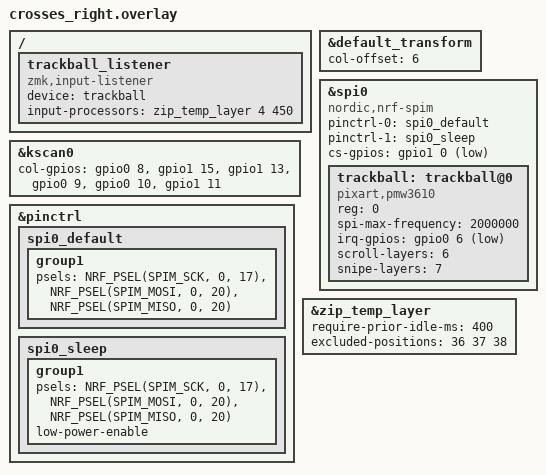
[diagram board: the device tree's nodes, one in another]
/*
 * Copyright (c) 2020 ZMK Contributors
 *
 * SPDX-License-Identifier: MIT
 */
 
#include "crosses.dtsi"
#include <input/processors.dtsi>

&default_transform {
    col-offset = <6>;
}; 

&kscan0 {
	col-gpios
		= <&gpio0 8 (GPIO_ACTIVE_HIGH | GPIO_PULL_DOWN)>
		, <&gpio1 15 (GPIO_ACTIVE_HIGH | GPIO_PULL_DOWN)>
		, <&gpio1 13 (GPIO_ACTIVE_HIGH | GPIO_PULL_DOWN)>
		, <&gpio0 9 (GPIO_ACTIVE_HIGH | GPIO_PULL_DOWN)>
		, <&gpio0 10  (GPIO_ACTIVE_HIGH | GPIO_PULL_DOWN)>
		, <&gpio1 11 (GPIO_ACTIVE_HIGH | GPIO_PULL_DOWN)>
		
		;
};


// trackball bus
&pinctrl {
    spi0_default: spi0_default {
        group1 {
            psels = <NRF_PSEL(SPIM_SCK, 0, 17)>,
                <NRF_PSEL(SPIM_MOSI, 0, 20)>,
                <NRF_PSEL(SPIM_MISO, 0, 20)>;
        };
    };

    spi0_sleep: spi0_sleep {
        group1 {
            psels = <NRF_PSEL(SPIM_SCK, 0, 17)>,
                <NRF_PSEL(SPIM_MOSI, 0, 20)>,
                <NRF_PSEL(SPIM_MISO, 0, 20)>;
            low-power-enable;
        };
    };
};

&spi0 {
    status = "okay";
    compatible = "nordic,nrf-spim";
    pinctrl-0 = <&spi0_default>;
    pinctrl-1 = <&spi0_sleep>;
    pinctrl-names = "default", "sleep";
    cs-gpios = <&gpio1 0 GPIO_ACTIVE_LOW>;

    trackball: trackball@0 {
        status = "okay";
        compatible = "pixart,pmw3610";
        reg = <0>;
        spi-max-frequency = <2000000>;
        irq-gpios = <&gpio0 6 (GPIO_ACTIVE_LOW | GPIO_PULL_UP)>;
        // índices iguais aos #define do crosses.keymap: SCROLL 6, SNIPE 7 (acima do MOUSE 4)
        // O layer Mouse é ligado pelo zip_temp_layer do ZMK (abaixo), não pelo automouse do driver.
        scroll-layers = <6>;
        snipe-layers = <7>;
    };
};





/ {
    trackball_listener {
        compatible = "zmk,input-listener";
        device = <&trackball>;
        // mexer a bola liga o layer Mouse (4) por 450 ms após o último movimento
        input-processors = <&zip_temp_layer 4 450>;
    };
};

// Automouse nativo do ZMK:
//  - require-prior-idle-ms: não liga o Mouse se alguma tecla foi apertada nos últimos 400 ms
//    (a bola tremendo enquanto você digita não vira clique)
//  - excluded-positions: os três polegares esquerdos (clique dir. · Scroll · clique) não desligam o
//    layer; qualquer outra tecla desliga na hora
&zip_temp_layer {
    require-prior-idle-ms = <400>;
    excluded-positions = <36 37 38>;
};
